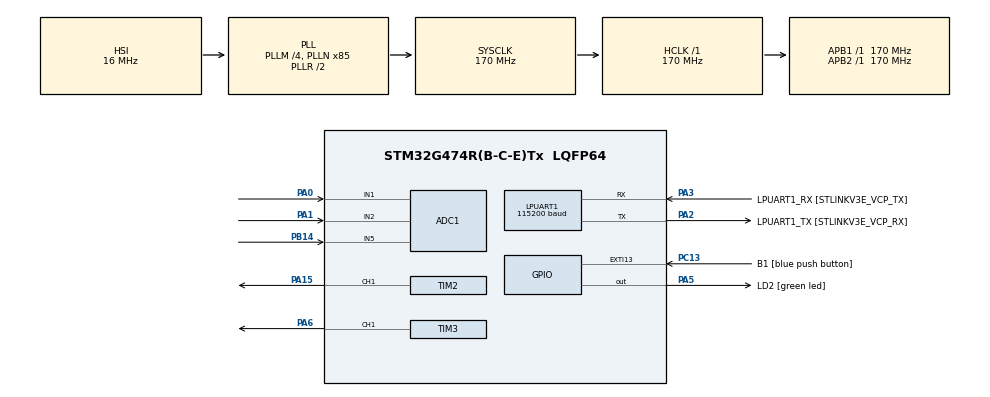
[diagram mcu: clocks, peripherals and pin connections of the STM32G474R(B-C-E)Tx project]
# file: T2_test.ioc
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ADC1.Channel-0\#ChannelRegularConversion=ADC_CHANNEL_1
ADC1.Channel-1\#ChannelRegularConversion=ADC_CHANNEL_2
ADC1.Channel-2\#ChannelRegularConversion=ADC_CHANNEL_5
ADC1.ContinuousConvMode=ENABLE
ADC1.DMAContinuousRequests=ENABLE
ADC1.NbrOfConversion=3
ADC1.NbrOfConversionFlag=1
ADC1.OffsetNumber-0\#ChannelRegularConversion=ADC_OFFSET_NONE
ADC1.OffsetNumber-1\#ChannelRegularConversion=ADC_OFFSET_NONE
ADC1.OffsetNumber-2\#ChannelRegularConversion=ADC_OFFSET_NONE
ADC1.Rank-0\#ChannelRegularConversion=1
ADC1.Rank-1\#ChannelRegularConversion=2
ADC1.Rank-2\#ChannelRegularConversion=3
ADC1.SamplingTime-0\#ChannelRegularConversion=ADC_SAMPLETIME_2CYCLES_5
ADC1.SamplingTime-1\#ChannelRegularConversion=ADC_SAMPLETIME_2CYCLES_5
ADC1.SamplingTime-2\#ChannelRegularConversion=ADC_SAMPLETIME_2CYCLES_5
ADC1.master=1
Dma.ADC1.0.Direction=DMA_PERIPH_TO_MEMORY
Dma.ADC1.0.EventEnable=DISABLE
Dma.ADC1.0.Instance=DMA1_Channel1
Dma.ADC1.0.MemDataAlignment=DMA_MDATAALIGN_HALFWORD
Dma.ADC1.0.MemInc=DMA_MINC_ENABLE
Dma.ADC1.0.Mode=DMA_CIRCULAR
Dma.ADC1.0.PeriphDataAlignment=DMA_PDATAALIGN_HALFWORD
Dma.ADC1.0.PeriphInc=DMA_PINC_DISABLE
Dma.ADC1.0.Polarity=HAL_DMAMUX_REQ_GEN_RISING
Dma.ADC1.0.Priority=DMA_PRIORITY_LOW
Dma.ADC1.0.RequestNumber=1
Dma.ADC1.0.SignalID=NONE
Dma.ADC1.0.SyncEnable=DISABLE
Dma.ADC1.0.SyncPolarity=HAL_DMAMUX_SYNC_NO_EVENT
Dma.ADC1.0.SyncRequestNumber=1
Dma.ADC1.0.SyncSignalID=NONE
Dma.Request0=ADC1
LPUART1.BaudRate=115200
LPUART1.WordLength=UART_WORDLENGTH_8B
Mcu.Family=STM32G4
Mcu.Name=STM32G474R(B-C-E)Tx
Mcu.Package=LQFP64
NVIC.ADC1_2_IRQn=true\:0\:0\:false\:false\:true\:true\:true\:true
NVIC.DMA1_Channel1_IRQn=true\:0\:0\:false\:false\:true\:false\:true\:true
NVIC.EXTI15_10_IRQn=true\:0\:0\:false\:false\:true\:true\:true\:true
NVIC.PriorityGroup=NVIC_PRIORITYGROUP_4
NVIC.TIM2_IRQn=true\:0\:0\:false\:false\:true\:true\:true\:true
NVIC.TIM3_IRQn=true\:0\:0\:false\:false\:true\:true\:true\:true
PA0.Mode=IN1-Single-Ended
PA0.Signal=ADC1_IN1
PA1.Mode=IN2-Single-Ended
PA1.Signal=ADC1_IN2
PA13.GPIO_Label=T_SWDIO
PA13.Mode=Serial_Wire
PA13.Signal=SYS_JTMS-SWDIO
PA14.GPIO_Label=T_SWCLK
PA14.Mode=Serial_Wire
PA14.Signal=SYS_JTCK-SWCLK
PA15.Signal=S_TIM2_CH1
PA2.GPIO_Label=LPUART1_TX [STLINKV3E_VCP_RX]
PA2.Mode=Asynchronous
PA2.Signal=LPUART1_TX
PA3.GPIO_Label=LPUART1_RX [STLINKV3E_VCP_TX]
PA3.Mode=Asynchronous
PA3.Signal=LPUART1_RX
PA5.GPIO_Label=LD2 [green led]
PA5.Signal=GPIO_Output
PA6.Signal=S_TIM3_CH1
PB14.Mode=IN5-Single-Ended
PB14.Signal=ADC1_IN5
PB3.GPIO_Label=T_SWO
PB3.Signal=SYS_JTDO-SWO
PC13.GPIO_Label=B1 [blue push button]
PC13.Signal=GPXTI13
PC14-OSC32_IN.Mode=LSE-External-Oscillator
PC14-OSC32_IN.Signal=RCC_OSC32_IN
PC15-OSC32_OUT.Mode=LSE-External-Oscillator
PC15-OSC32_OUT.Signal=RCC_OSC32_OUT
PF0-OSC_IN.Mode=HSE-External-Oscillator
PF0-OSC_IN.Signal=RCC_OSC_IN
PF1-OSC_OUT.Mode=HSE-External-Oscillator
PF1-OSC_OUT.Signal=RCC_OSC_OUT
ProjectManager.HeapSize=0x200
ProjectManager.StackSize=0x400
ProjectManager.TargetToolchain=STM32CubeIDE
RCC.ADC12Freq_Value=170000000
RCC.ADC345Freq_Value=170000000
RCC.AHBFreq_Value=170000000
RCC.APB1Freq_Value=170000000
RCC.APB1TimFreq_Value=170000000
RCC.APB2Freq_Value=170000000
RCC.APB2TimFreq_Value=170000000
RCC.CortexFreq_Value=170000000
RCC.EXTERNAL_CLOCK_VALUE=12288000
RCC.HCLKFreq_Value=170000000
RCC.HSE_VALUE=24000000
RCC.HSI48_VALUE=48000000
RCC.HSI_VALUE=16000000
RCC.PLLM=RCC_PLLM_DIV4
RCC.PLLN=85
RCC.RTCClockSelection=RCC_RTCCLKSOURCE_LSE
RCC.SYSCLKFreq_VALUE=170000000
RCC.SYSCLKSource=RCC_SYSCLKSOURCE_PLLCLK
RCC.USBFreq_Value=170000000
RCC.VCOOutputFreq_Value=340000000
SH.S_TIM2_CH1.0=TIM2_CH1,PWM Generation1 CH1
SH.S_TIM3_CH1.0=TIM3_CH1,PWM Generation1 CH1
TIM2.Channel-PWM\ Generation1\ CH1=TIM_CHANNEL_1
TIM2.PeriodNoDither=400000
TIM2.Prescaler=169
TIM3.Channel-PWM\ Generation1\ CH1=TIM_CHANNEL_1
TIM3.PeriodNoDither=400
TIM3.Prescaler=169
VP_SYS_VS_DBSignals.Mode=DisableDeadBatterySignals
VP_TIM2_VS_ClockSourceINT.Mode=Internal
VP_TIM3_VS_ClockSourceINT.Mode=Internal
board=NUCLEO-G474RE

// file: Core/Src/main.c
/* USER CODE BEGIN Header */
/**
  ******************************************************************************
  * @file           : main.c
  * @brief          : Main program body
  ******************************************************************************
  * @attention
  *
  * Copyright (c) 2024 STMicroelectronics.
  * All rights reserved.
  *
  * This software is licensed under terms that can be found in the LICENSE file
  * in the root directory of this software component.
  * If no LICENSE file comes with this software, it is provided AS-IS.
  *
  ******************************************************************************
  */
/* USER CODE END Header */
#include "main.h"

ADC_HandleTypeDef hadc1;
DMA_HandleTypeDef hdma_adc1;

UART_HandleTypeDef hlpuart1;

TIM_HandleTypeDef htim2;
TIM_HandleTypeDef htim3;

/* USER CODE BEGIN PV */
uint16_t ADC_RawRead[300] = {};
uint16_t lower;
uint32_t realtime;
/* USER CODE END PV */

void SystemClock_Config(void);
static void MX_GPIO_Init(void);
static void MX_DMA_Init(void);
static void MX_LPUART1_UART_Init(void);
static void MX_ADC1_Init(void);
static void MX_TIM2_Init(void);
static void MX_TIM3_Init(void);

int main(void)
{

  /* MCU Configuration--------------------------------------------------------*/

  /* Reset of all peripherals, Initializes the Flash interface and the Systick. */
  HAL_Init();

  /* Configure the system clock */
  SystemClock_Config();

  /* Initialize all configured peripherals */
  MX_GPIO_Init();
  MX_DMA_Init();
  MX_LPUART1_UART_Init();
  MX_ADC1_Init();
  MX_TIM2_Init();
  MX_TIM3_Init();
  /* USER CODE BEGIN 2 */
  HAL_ADCEx_Calibration_Start(&hadc1, ADC_SINGLE_ENDED);
  HAL_ADC_Start_DMA(&hadc1, ADC_RawRead, 300);
  HAL_TIM_Base_Start(&htim2);
  HAL_TIM_PWM_Start(&htim2, TIM_CHANNEL_1);
  /* USER CODE END 2 */

  /* Infinite loop */
  while (1)
  {

    /* USER CODE BEGIN 3 */

	  __HAL_TIM_SET_COMPARE(&htim2, TIM_CHANNEL_1, 300000);

  }
  /* USER CODE END 3 */
}

void SystemClock_Config(void)
{
  RCC_OscInitTypeDef RCC_OscInitStruct = {0};
  RCC_ClkInitTypeDef RCC_ClkInitStruct = {0};

  /** Configure the main internal regulator output voltage
  */
  HAL_PWREx_ControlVoltageScaling(PWR_REGULATOR_VOLTAGE_SCALE1_BOOST);

  /** Initializes the RCC Oscillators according to the specified parameters
  * in the RCC_OscInitTypeDef structure.
  */
  RCC_OscInitStruct.OscillatorType = RCC_OSCILLATORTYPE_HSI;
  RCC_OscInitStruct.HSIState = RCC_HSI_ON;
  RCC_OscInitStruct.HSICalibrationValue = RCC_HSICALIBRATION_DEFAULT;
  RCC_OscInitStruct.PLL.PLLState = RCC_PLL_ON;
  RCC_OscInitStruct.PLL.PLLSource = RCC_PLLSOURCE_HSI;
  RCC_OscInitStruct.PLL.PLLM = RCC_PLLM_DIV4;
  RCC_OscInitStruct.PLL.PLLN = 85;
  RCC_OscInitStruct.PLL.PLLP = RCC_PLLP_DIV2;
  RCC_OscInitStruct.PLL.PLLQ = RCC_PLLQ_DIV2;
  RCC_OscInitStruct.PLL.PLLR = RCC_PLLR_DIV2;
  if (HAL_RCC_OscConfig(&RCC_OscInitStruct) != HAL_OK)
  {
    Error_Handler();
  }

  /** Initializes the CPU, AHB and APB buses clocks
  */
  RCC_ClkInitStruct.ClockType = RCC_CLOCKTYPE_HCLK|RCC_CLOCKTYPE_SYSCLK
                              |RCC_CLOCKTYPE_PCLK1|RCC_CLOCKTYPE_PCLK2;
  RCC_ClkInitStruct.SYSCLKSource = RCC_SYSCLKSOURCE_PLLCLK;
  RCC_ClkInitStruct.AHBCLKDivider = RCC_SYSCLK_DIV1;
  RCC_ClkInitStruct.APB1CLKDivider = RCC_HCLK_DIV1;
  RCC_ClkInitStruct.APB2CLKDivider = RCC_HCLK_DIV1;

  if (HAL_RCC_ClockConfig(&RCC_ClkInitStruct, FLASH_LATENCY_4) != HAL_OK)
  {
    Error_Handler();
  }
}

static void MX_ADC1_Init(void)
{

  ADC_MultiModeTypeDef multimode = {0};
  ADC_ChannelConfTypeDef sConfig = {0};

  /** Common config
  */
  hadc1.Instance = ADC1;
  hadc1.Init.ClockPrescaler = ADC_CLOCK_SYNC_PCLK_DIV4;
  hadc1.Init.Resolution = ADC_RESOLUTION_12B;
  hadc1.Init.DataAlign = ADC_DATAALIGN_RIGHT;
  hadc1.Init.GainCompensation = 0;
  hadc1.Init.ScanConvMode = ADC_SCAN_ENABLE;
  hadc1.Init.EOCSelection = ADC_EOC_SINGLE_CONV;
  hadc1.Init.LowPowerAutoWait = DISABLE;
  hadc1.Init.ContinuousConvMode = ENABLE;
  hadc1.Init.NbrOfConversion = 3;
  hadc1.Init.DiscontinuousConvMode = DISABLE;
  hadc1.Init.ExternalTrigConv = ADC_SOFTWARE_START;
  hadc1.Init.ExternalTrigConvEdge = ADC_EXTERNALTRIGCONVEDGE_NONE;
  hadc1.Init.DMAContinuousRequests = ENABLE;
  hadc1.Init.Overrun = ADC_OVR_DATA_PRESERVED;
  hadc1.Init.OversamplingMode = DISABLE;
  if (HAL_ADC_Init(&hadc1) != HAL_OK)
  {
    Error_Handler();
  }

  /** Configure the ADC multi-mode
  */
  multimode.Mode = ADC_MODE_INDEPENDENT;
  if (HAL_ADCEx_MultiModeConfigChannel(&hadc1, &multimode) != HAL_OK)
  {
    Error_Handler();
  }

  /** Configure Regular Channel
  */
  sConfig.Channel = ADC_CHANNEL_1;
  sConfig.Rank = ADC_REGULAR_RANK_1;
  sConfig.SamplingTime = ADC_SAMPLETIME_2CYCLES_5;
  sConfig.SingleDiff = ADC_SINGLE_ENDED;
  sConfig.OffsetNumber = ADC_OFFSET_NONE;
  sConfig.Offset = 0;
  if (HAL_ADC_ConfigChannel(&hadc1, &sConfig) != HAL_OK)
  {
    Error_Handler();
  }

  /** Configure Regular Channel
  */
  sConfig.Channel = ADC_CHANNEL_2;
  sConfig.Rank = ADC_REGULAR_RANK_2;
  if (HAL_ADC_ConfigChannel(&hadc1, &sConfig) != HAL_OK)
  {
    Error_Handler();
  }

  /** Configure Regular Channel
  */
  sConfig.Channel = ADC_CHANNEL_5;
  sConfig.Rank = ADC_REGULAR_RANK_3;
  if (HAL_ADC_ConfigChannel(&hadc1, &sConfig) != HAL_OK)
  {
    Error_Handler();
  }

}

static void MX_LPUART1_UART_Init(void)
{

  hlpuart1.Instance = LPUART1;
  hlpuart1.Init.BaudRate = 115200;
  hlpuart1.Init.WordLength = UART_WORDLENGTH_8B;
  hlpuart1.Init.StopBits = UART_STOPBITS_1;
  hlpuart1.Init.Parity = UART_PARITY_NONE;
  hlpuart1.Init.Mode = UART_MODE_TX_RX;
  hlpuart1.Init.HwFlowCtl = UART_HWCONTROL_NONE;
  hlpuart1.Init.OneBitSampling = UART_ONE_BIT_SAMPLE_DISABLE;
  hlpuart1.Init.ClockPrescaler = UART_PRESCALER_DIV1;
  hlpuart1.AdvancedInit.AdvFeatureInit = UART_ADVFEATURE_NO_INIT;
  if (HAL_UART_Init(&hlpuart1) != HAL_OK)
  {
    Error_Handler();
  }
  if (HAL_UARTEx_SetTxFifoThreshold(&hlpuart1, UART_TXFIFO_THRESHOLD_1_8) != HAL_OK)
  {
    Error_Handler();
  }
  if (HAL_UARTEx_SetRxFifoThreshold(&hlpuart1, UART_RXFIFO_THRESHOLD_1_8) != HAL_OK)
  {
    Error_Handler();
  }
  if (HAL_UARTEx_DisableFifoMode(&hlpuart1) != HAL_OK)
  {
    Error_Handler();
  }

}

static void MX_TIM2_Init(void)
{

  TIM_ClockConfigTypeDef sClockSourceConfig = {0};
  TIM_MasterConfigTypeDef sMasterConfig = {0};
  TIM_OC_InitTypeDef sConfigOC = {0};

  htim2.Instance = TIM2;
  htim2.Init.Prescaler = 169;
  htim2.Init.CounterMode = TIM_COUNTERMODE_UP;
  htim2.Init.Period = 400000;
  htim2.Init.ClockDivision = TIM_CLOCKDIVISION_DIV1;
  htim2.Init.AutoReloadPreload = TIM_AUTORELOAD_PRELOAD_DISABLE;
  if (HAL_TIM_Base_Init(&htim2) != HAL_OK)
  {
    Error_Handler();
  }
  sClockSourceConfig.ClockSource = TIM_CLOCKSOURCE_INTERNAL;
  if (HAL_TIM_ConfigClockSource(&htim2, &sClockSourceConfig) != HAL_OK)
  {
    Error_Handler();
  }
  if (HAL_TIM_PWM_Init(&htim2) != HAL_OK)
  {
    Error_Handler();
  }
  sMasterConfig.MasterOutputTrigger = TIM_TRGO_RESET;
  sMasterConfig.MasterSlaveMode = TIM_MASTERSLAVEMODE_DISABLE;
  if (HAL_TIMEx_MasterConfigSynchronization(&htim2, &sMasterConfig) != HAL_OK)
  {
    Error_Handler();
  }
  sConfigOC.OCMode = TIM_OCMODE_PWM1;
  sConfigOC.Pulse = 0;
  sConfigOC.OCPolarity = TIM_OCPOLARITY_HIGH;
  sConfigOC.OCFastMode = TIM_OCFAST_DISABLE;
  if (HAL_TIM_PWM_ConfigChannel(&htim2, &sConfigOC, TIM_CHANNEL_1) != HAL_OK)
  {
    Error_Handler();
  }
  HAL_TIM_MspPostInit(&htim2);

}

static void MX_TIM3_Init(void)
{

  TIM_ClockConfigTypeDef sClockSourceConfig = {0};
  TIM_MasterConfigTypeDef sMasterConfig = {0};
  TIM_OC_InitTypeDef sConfigOC = {0};

  htim3.Instance = TIM3;
  htim3.Init.Prescaler = 169;
  htim3.Init.CounterMode = TIM_COUNTERMODE_UP;
  htim3.Init.Period = 400;
  htim3.Init.ClockDivision = TIM_CLOCKDIVISION_DIV1;
  htim3.Init.AutoReloadPreload = TIM_AUTORELOAD_PRELOAD_DISABLE;
  if (HAL_TIM_Base_Init(&htim3) != HAL_OK)
  {
    Error_Handler();
  }
  sClockSourceConfig.ClockSource = TIM_CLOCKSOURCE_INTERNAL;
  if (HAL_TIM_ConfigClockSource(&htim3, &sClockSourceConfig) != HAL_OK)
  {
    Error_Handler();
  }
  if (HAL_TIM_PWM_Init(&htim3) != HAL_OK)
  {
    Error_Handler();
  }
  sMasterConfig.MasterOutputTrigger = TIM_TRGO_RESET;
  sMasterConfig.MasterSlaveMode = TIM_MASTERSLAVEMODE_DISABLE;
  if (HAL_TIMEx_MasterConfigSynchronization(&htim3, &sMasterConfig) != HAL_OK)
  {
    Error_Handler();
  }
  sConfigOC.OCMode = TIM_OCMODE_PWM1;
  sConfigOC.Pulse = 0;
  sConfigOC.OCPolarity = TIM_OCPOLARITY_HIGH;
  sConfigOC.OCFastMode = TIM_OCFAST_DISABLE;
  if (HAL_TIM_PWM_ConfigChannel(&htim3, &sConfigOC, TIM_CHANNEL_1) != HAL_OK)
  {
    Error_Handler();
  }
  HAL_TIM_MspPostInit(&htim3);

}

static void MX_DMA_Init(void)
{

  /* DMA controller clock enable */
  __HAL_RCC_DMAMUX1_CLK_ENABLE();
  __HAL_RCC_DMA1_CLK_ENABLE();

  /* DMA interrupt init */
  /* DMA1_Channel1_IRQn interrupt configuration */
  HAL_NVIC_SetPriority(DMA1_Channel1_IRQn, 0, 0);
  HAL_NVIC_EnableIRQ(DMA1_Channel1_IRQn);

}

static void MX_GPIO_Init(void)
{
  GPIO_InitTypeDef GPIO_InitStruct = {0};

  /* GPIO Ports Clock Enable */
  __HAL_RCC_GPIOC_CLK_ENABLE();
  __HAL_RCC_GPIOF_CLK_ENABLE();
  __HAL_RCC_GPIOA_CLK_ENABLE();
  __HAL_RCC_GPIOB_CLK_ENABLE();

  /*Configure GPIO pin Output Level */
  HAL_GPIO_WritePin(LD2_GPIO_Port, LD2_Pin, GPIO_PIN_RESET);

  /*Configure GPIO pin : B1_Pin */
  GPIO_InitStruct.Pin = B1_Pin;
  GPIO_InitStruct.Mode = GPIO_MODE_IT_RISING;
  GPIO_InitStruct.Pull = GPIO_NOPULL;
  HAL_GPIO_Init(B1_GPIO_Port, &GPIO_InitStruct);

  /*Configure GPIO pin : LD2_Pin */
  GPIO_InitStruct.Pin = LD2_Pin;
  GPIO_InitStruct.Mode = GPIO_MODE_OUTPUT_PP;
  GPIO_InitStruct.Pull = GPIO_NOPULL;
  GPIO_InitStruct.Speed = GPIO_SPEED_FREQ_LOW;
  HAL_GPIO_Init(LD2_GPIO_Port, &GPIO_InitStruct);

  /* EXTI interrupt init*/
  HAL_NVIC_SetPriority(EXTI15_10_IRQn, 0, 0);
  HAL_NVIC_EnableIRQ(EXTI15_10_IRQn);

}

/* USER CODE BEGIN 4 */
void HAL_TIM_PeriodElapsedCallback(TIM_HandleTypeDef *htim)
{
if(htim == &htim2)
{
	lower += 1;
}
}
/* USER CODE END 4 */

void Error_Handler(void)
{
  __disable_irq();
  while (1)
  {
  }
}
